# AVR32LA20 register map
Vendor: Atmel; File version: 1.0
CPU: other r0p0, little endian, no MPU, no FPU, 4 interrupt priority bits
Registers are 8-bit, read-write, reset 0x0 unless marked. A register's access mark holds for its fields unless they carry their own. Offsets are from the block's base; [hi:lo] are bit positions; {n}, {i} and the like mark numbered series.

## USART0 — Universal Synchronous and Asynchronous Receiver and Transmitter
Base 0x00800800
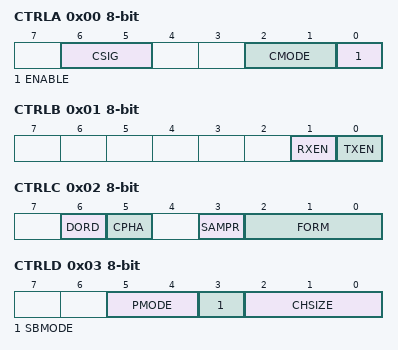
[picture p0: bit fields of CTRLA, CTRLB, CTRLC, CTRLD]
0x00 CTRLA — Control A
  [6:5] CSIG — Communication Signals
    0=NORMAL (Normal Asynchronous USART, Synchronous USART or SPI Host); 1=RS485 (Asynchronous USART in RS485 mode); 2=HANDSHAKE (Asynchronous USART with Hardware Handshake); 3=CLKDIS (SPI Host or Synchronous USART host without Clock Output)
  [2:1] CMODE — Communication Mode
    0=ASYNCHRONOUS (Asynchronous Mode); 1=SYNCCLIENT (Synchronous USART, client mode); 2=SYNCHOST (Synchronous USART, host mode); 3=SPIHOST (SPI Host Mode)
  [0] ENABLE
0x01 CTRLB — Control B
  [1] RXEN — Receiver enable
  [0] TXEN — Transmitter enable
0x02 CTRLC — Control C
  [6] DORD — Data Order
    0=LSB (LSb of the data word is transmitted first); 1=MSB (MSb of the data word is transmitted first)
  [5] CPHA — Clock Phase
    0=LEADEDGE (Data is sampled on leading/first edge of SCK); 1=TRAILEDGE (Data is sampled on trailing/last edge of SCK)
  [3] SAMPR — Sample Rate
    0=16X (16x oversampling); 1=8X (8x oversampling (double speed))
  [2:0] FORM — Frame Format
    0=NORMAL (Normal USART frame); 1=AUTOBAUD (Auto-baud mode); 4=LINHOST (LIN Host mode); 5=LINCLIENT (LIN Client mode)
0x03 CTRLD — Control D
  [5:4] PMODE — Parity Mode
    0=DISABLED (No Parity); 2=EVEN (Even Parity); 3=ODD (Odd Parity)
  [3] SBMODE — Stop Bit Mode
    0=1BIT (1 stop bit); 1=2BIT (2 stop bits)
  [2:0] CHSIZE — Character Size
    {v}={v+5}BIT (Character size: {v+5} bit) (v=0..3); 6=9BITL (Character size: 9 bit read low byte first); 7=9BITH (Character size: 9 bit read high byte first)
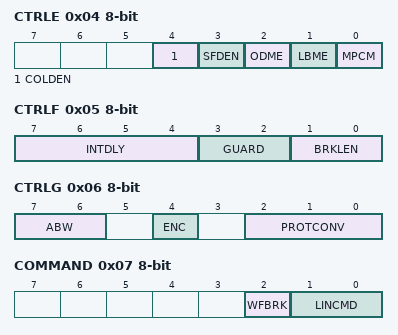
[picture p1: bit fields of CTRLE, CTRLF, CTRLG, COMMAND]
0x04 CTRLE — Control E
  [4] COLDEN — Collision Detection Enable
  [3] SFDEN — Start Frame Detection Enable
  [2] ODME — Open Drain Mode Enable
  [1] LBME — Loop-back Mode Enable
  [0] MPCM — Multi-processor Communication Mode
0x05 CTRLF — Control F
  [7:4] INTDLY — Inter-byte Delay
  [3:2] GUARD — Guard Time
    0=1BIT (Guard time is 1 bit time); 1=4BIT (Guard time is 4 bit times); 2=8BIT (Guard time is 8 bit times); 3=14BIT (Guard time is 14 bit times)
  [1:0] BRKLEN — Break Length
    0=13BIT (Break field transmission is 13 bit time); 1=17BIT (Break field transmission is 17 bit time); 2=21BIT (Break field transmission is 21 bit time); 3=26BIT (Break field transmission is 26 bit time)
0x06 CTRLG — Control G
  [7:6] ABW — Auto Baud Window
    0=WDW0 (18% tolerance); 1=WDW1 (15% tolerance); 2=WDW2 (21% tolerance); 3=WDW3 (25% tolerance)
  [4] ENC — Encoding
  [2:0] PROTCONV — Protocol Converter
    0=NONE (Protocol conversion disabled. Normal data); 1=FIXED (Single char for both '0' and '1'. Frame error set if values don't match); 2=MASKED (CHARMASK works as a mask); 3=DUAL (CHARMASK defines second value for '1')
0x07 COMMAND
  [2] WFBRK — Wait for BREAK
  [1:0] LINCMD — LIN Command
    0=NORMAL (Normal USART frame); 1=BREAK (BREAK field transmitted when TXDATA is written); 2=HEADER (BREAK and SYNC and identifier are auto tramsmitted when TXDATA is writtent with identifier)
0x09 EVCTRL — Event Control
  [0] RXEI — Receive Event Input Enable
0x0A BAUD 16-bit (reset mask 0xFF) — Baud Rate
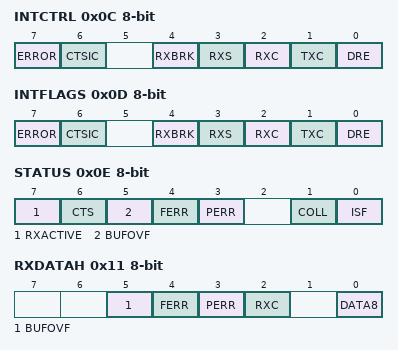
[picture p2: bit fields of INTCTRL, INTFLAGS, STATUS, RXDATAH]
0x0C INTCTRL — Interrupt Control
  [7] ERROR — Error Interrupt Enable
  [6] CTSIC — Clear to Send Input Change Interrupt Enable
  [4] RXBRK — Receive Break Interrupt Enable
  [3] RXS — Receiver Start Frame Interrupt Enable
  [2] RXC — Receive Complete Interrupt Enable
  [1] TXC — Transmit Complete Interrupt Enable
  [0] DRE — Data Register Empty Interrupt Enable
0x0D INTFLAGS — Interrupt Flags
  [7] ERROR — Error Interrupt Flag
  [6] CTSIC — Clear to Send Input Change Interrupt Flag
  [4] RXBRK — Receive Break Interrupt Flag
  [3] RXS — Receiver Start Frame Interrupt Flag
  [2] RXC ro — Receive Complete Interrupt Flag
  [1] TXC — Transmit Complete Interrupt Flag
  [0] DRE ro — Data Register Empty Interrupt Flag
0x0E STATUS
  [7] RXACTIVE ro — Receive Active
  [6] CTS ro — Clear to Send
  [5] BUFOVF ro — Buffer Overflow
  [4] FERR ro — Frame Error
  [3] PERR ro — Parity Error
  [1] COLL — Collision Detected
  [0] ISF — Inconsistent Sync Field
0x10 RXDATAL ro — Receive Data Low Byte
  [7:0] DATA — RX Data
0x11 RXDATAH ro — Receive Data
  [5] BUFOVF — Buffer Overflow
  [4] FERR — Frame Error
  [3] PERR — Parity Error
  [2] RXC — USART Receive Complete Interrupt Flag
  [0] DATA8 — Receiver Data Register
0x12 TXDATAL — Transmit Data Low Byte
  [7:0] DATA — Transmit Data Register
0x13 TXDATAH — Transmit Data High Byte
  [0] DATA8 — Transmit Data Register (CHSIZE=9bit)
{0x18+i} AUXDATA{i} (i=0..2) — Auxiliary Data {i}
0x1F DBGCTRL — Debug Control
  [0] DBGRUN — Debug Run
